# STM32H503xx register map
File version: 1.0
Registers are 32-bit, read-write, reset 0x0 unless marked. A register's access mark holds for its fields unless they carry their own. Offsets are from the block's base; [hi:lo] are bit positions; {n}, {i} and the like mark numbered series.

## RNG
Base 0x420C0800
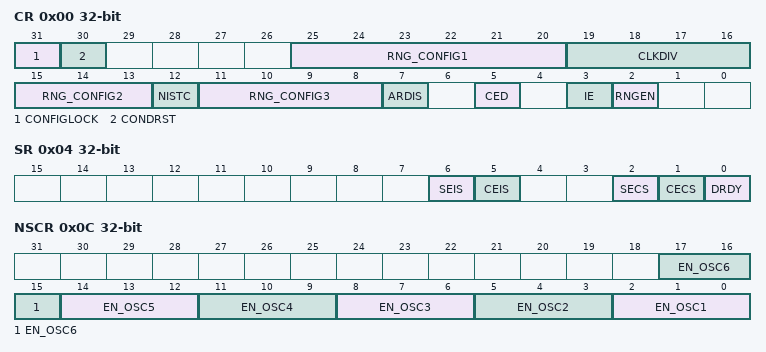
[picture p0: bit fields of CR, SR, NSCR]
0x00 CR — RNG control register
  [31] CONFIGLOCK — RNG configuration lock
  [30] CONDRST — Conditioning soft reset
  [25:20] RNG_CONFIG1 — RNG configuration 1
  [19:16] CLKDIV — Clock divider factor
    0=BY_1 (No clock division); 1=BY_2 (2 RNG clock cycles per internal RNG clock); 2=BY_4 (4 RNG clock cycles per internal RNG clock); 3=BY_8 (8 RNG clock cycles per internal RNG clock); 4=BY_16 (16 RNG clock cycles per internal RNG clock); 5=BY_32 (32 RNG clock cycles per internal RNG clock); 6=BY_64 (64 RNG clock cycles per internal RNG clock); 7=BY_128 (128 RNG clock cycles per internal RNG clock); 8=BY_256 (256 RNG clock cycles per internal RNG clock); 9=BY_512 (512 RNG clock cycles per internal RNG clock); 10=BY_1024 (1024 RNG clock cycles per internal RNG clock); 11=BY_2048 (2048 RNG clock cycles per internal RNG clock); 12=BY_4096 (4096 RNG clock cycles per internal RNG clock); 13=BY_8192 (8192 RNG clock cycles per internal RNG clock); 14=BY_16384 (16384 RNG clock cycles per internal RNG clock); 15=BY_32768 (32768 RNG clock cycles per internal RNG clock)
  [15:13] RNG_CONFIG2 — RNG configuration 2
  [12] NISTC — NIST custom
  [11:8] RNG_CONFIG3 — RNG configuration 3
  [7] ARDIS — Auto reset disable
  [5] CED — Clock error detection
  [3] IE — Interrupt enable
  [2] RNGEN — True random number generator enable
0x04 SR — RNG status register
  [6] SEIS, [5] CEIS, [2] SECS, [1] CECS, [0] DRDY
0x08 DR — RNG data register
0x0C NSCR — RNG noise source control register
  [3n-1:3n-3] EN_OSC{n} (n=1..6)
0x10 HTCR — RNG health test configuration register
  [31:0] HTCFG

## SBS — System configuration, Boot and Security
Base 0x44000400
0x10 HDPLCR — SBS HDPL Control Register
  [7:0] INCR_HDPL — Increment HDPL value
0x14 HDPLSR — SBS HDPL Status Register
  [7:0] HDPL — HDPL value
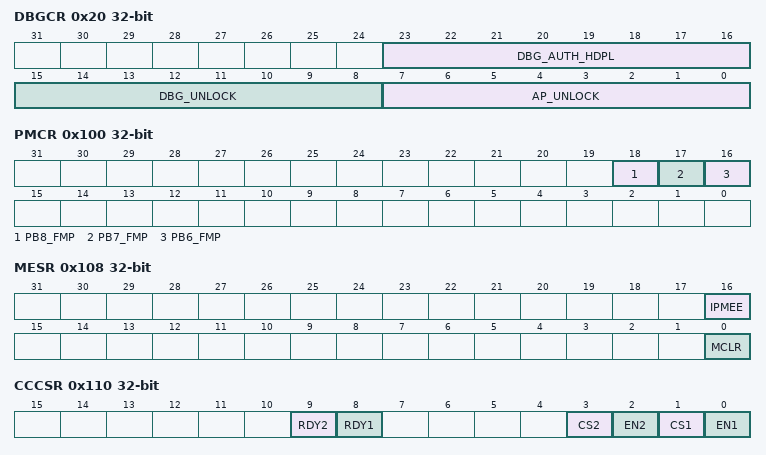
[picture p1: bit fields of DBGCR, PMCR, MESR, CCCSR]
0x20 DBGCR — SBS Debug Control Register
  [23:16] DBG_AUTH_HDPL — HDPL value when the debug should be effectively opened
  [15:8] DBG_UNLOCK — Open the debug when DBG_AUTH_HDPL is reached
  [7:0] AP_UNLOCK — Open the Access Port
0x24 DBGLOCKR — SBS Debug Lock Register
  [7:0] DBGCFG_LOCK — SBS_DBGLOCKR_DBGCFG_LOCK value
0x100 PMCR — SBS Product Mode & Config Register
  [18] PB8_FMP — Fast-mode Plus command on PB(8)
  [17] PB7_FMP — Fast-mode Plus command on PB(7)
  [16] PB6_FMP — Fast-mode Plus command on PB(6)
0x104 FPUIMR — SBS FPU Interrupt Mask Register
  [5:0] FPU_IE — All FPU interrupts enable
0x108 MESR — SBS Memory Erase Status Register
  [16] IPMEE — Status of End of Erase for ICache and PKA RAMs
  [0] MCLR — Status of Erase after Reset
0x110 CCCSR — SBS Compensation Cell Control & Status Register
  [9] RDY2 — VDDIO compensation cell ready flag
  [8] RDY1 — VDD compensation cell ready flag
  [3] CS2 — Code selection for VDDIO power rail
  [2] EN2 — Enable compensation cell for VDDIO power rail
  [1] CS1 — Code selection for VDD power rail
  [0] EN1 — Enable compensation cell for VDD power rail
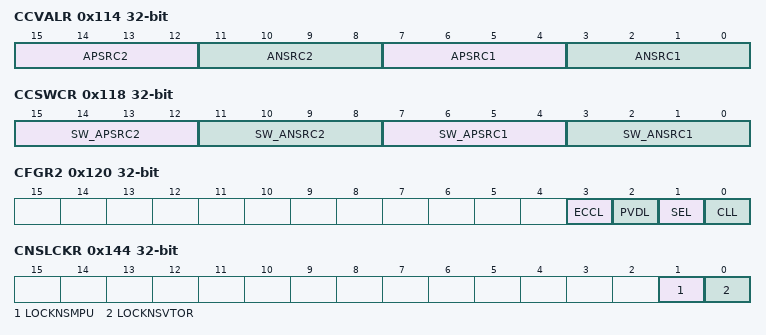
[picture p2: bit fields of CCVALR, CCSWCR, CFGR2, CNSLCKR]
0x114 CCVALR — SBS Compensation Cell Value Register
  [15:12] APSRC2 — PMOS compensation value
  [11:8] ANSRC2 — NMOS compensation value
  [7:4] APSRC1 — PMOS compensation value
  [3:0] ANSRC1 — NMOS compensation value
0x118 CCSWCR — SBS Compensation Cell for I/Os sw code Register
  [15:12] SW_APSRC2 — PMOS compensation code for VDDIO Power Rail
  [11:8] SW_ANSRC2 — NMOS compensation code for VDDIO Power Rail
  [7:4] SW_APSRC1 — PMOS compensation code for VDD Power Rail
  [3:0] SW_ANSRC1 — NMOS compensation code for VDD Power Rail
0x120 CFGR2 — SBS Class B Register
  [3] ECCL — Flash ECC Lock
  [2] PVDL — PVD Lock
  [1] SEL — SRAM ECC Lock
  [0] CLL — Core Lockup Lock
0x144 CNSLCKR — SBS CPU Non-secure Lock Register
  [1] LOCKNSMPU — Disable Non-Secure MPU registers writes by SW or debug agent
  [0] LOCKNSVTOR — Disable VTOR_NS register writes by SW or debug agent
0x14C ECCNMIR — SBS FLITF ECC NMI MASK Register
  [0] ECCNMI_MASK_EN — Disable NMI in case of double ECC error in flash interface
